# cmem7 register map
File version: 1.0
Registers are 32-bit, read-write, reset 0x0 unless marked. A register's access mark holds for its fields unless they carry their own. Offsets are from the block's base; [hi:lo] are bit positions; {n}, {i} and the like mark numbered series; 'fields as' and 'values as' point back to an identical list.

## USB
Base 0x41300000
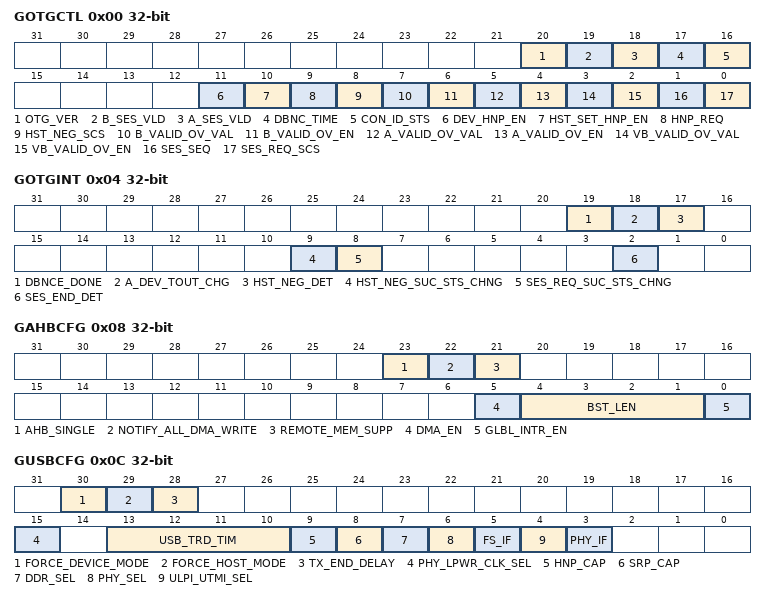
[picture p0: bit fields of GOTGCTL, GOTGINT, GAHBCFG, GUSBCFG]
0x00 GOTGCTL — Control and Status register
  [20] OTG_VER — If 0, OTG Version 1.3. If 1, OTG Version 2.0.
  [19] B_SES_VLD ro — B-Session Valid as a host
  [18] A_SES_VLD ro — A-Session Valid as a host
  [17] DBNC_TIME ro — the debounce time of a detected connection as a host
    0=DBNC_TIME_LONG (Long debounce time, used for physical connections (100ms + 2.5us)); 1=DBNC_TIME_SHORT (Short debounce time, used for soft connections (2.5us))
  [16] CON_ID_STS ro — Connector ID Status
    0=CON_ID_STS_A_DEVICE (in A-Device mode); 1=CON_ID_STS_B_DEVICE (in B-Device mode)
  [11] DEV_HNP_EN — Device HNP Enabled as a device
  [10] HST_SET_HNP_EN — Host Set HNP Enable as a host
  [9] HNP_REQ — sets this bit to initiate an HNP request to the connected USB host as a device
  [8] HST_NEG_SCS ro — sets when host negotiation is successful as a device.
  [7] B_VALID_OV_VAL — set Override value for Bvalid signal when GOTGCTL.BvalidOvEn is set as a device.
  [6] B_VALID_OV_EN — enable/disable the software to override the Bvalid signal using the GOTGCTL.BvalidOvVal as a device.
  [5] A_VALID_OV_VAL — set Override value for Avalid signal when GOTGCTL.AvalidOvEn is set as a host
  [4] A_VALID_OV_EN — enable/disable the software to override the Avalid signal using the GOTGCTL.AvalidOvVal as a host
  [3] VB_VALID_OV_VAL — set Override value for vbusvalid signal when GOTGCTL.VbvalidOvEn is set as a host
  [2] VB_VALID_OV_EN — enable/disable the software to override the Bvalid signal using the GOTGCTL.VbvalidOvVal as a host
  [1] SES_SEQ — set to initiate a session request on the USB as a device
  [0] SES_REQ_SCS ro — set when a session request initiation is successful as a device
0x04 GOTGINT — OTG interrupt Register
  [19] DBNCE_DONE — debounce is completed after the device connect as a host
  [18] A_DEV_TOUT_CHG — A-device has timed out while waiting for the B-device to connect
  [17] HST_NEG_DET — if set, detects a host negotiation request on the USB
  [9] HST_NEG_SUC_STS_CHNG — Host Negotiation Success Status Change
  [8] SES_REQ_SUC_STS_CHNG — Session Request Success Status Change
  [2] SES_END_DET — Set when the utmiotg_bvalid signal is deasserted
0x08 GAHBCFG — AHB Configuration Register
  [23] AHB_SINGLE — supports Single transfers for the remaining data in a transfer
  [22] NOTIFY_ALL_DMA_WRITE — enable the System DMA Done functionality for all the DMA write Transactions corresponding to the Channel/Endpoint
  [21] REMOTE_MEM_SUPP — enable the functionality to wait for the system DMA Done Signal for the DMA Write Transfers
  [5] DMA_EN — DMA enable
  [4:1] BST_LEN — Burst Length/Type
    0=BST_LEN_SINGLE (Single); 1=BST_LEN_INCR (INCR); 3=BST_LEN_INCR4 (INCR4); 5=BST_LEN_INCR8 (INCR8); 7=BST_LEN_INCR16 (INCR16)
  [0] GLBL_INTR_EN — Global Interrupt Enable
0x0C GUSBCFG — USB Configuration Register
  [30] FORCE_DEVICE_MODE
  [29] FORCE_HOST_MODE
  [28] TX_END_DELAY — Tx End Delay as a device
  [15] PHY_LPWR_CLK_SEL — 0, 480-MHz Internal PLL clock. 1, 48-MHz External Clock
  [13:10] USB_TRD_TIM — Specifies the response time for a MAC request to the Packet FIFO Controller (PFC) to fetch data from the DFIFO (SPRAM) as a device.
    5=When the MAC interface is 16-bit UTMI+; 9=When the MAC interface is 8-bit UTMI+
  [9] HNP_CAP — HNP-Capable
  [8] SRP_CAP — SRP-Capable
  [7] DDR_SEL — 0, Single Data Rate ULPI Interface, with 8-bit-wide data bus. 1, Double Data Rate ULPI Interface, with 4-bit-wide data bus
  [6] PHY_SEL — 0, USB 2.0 High-Speed PHY. 1, USB 1.1 full-speed serial transceiver
  [5] FS_IF — 1, 3-pin bidirectional. 0, 6-pin unidirectional
  [4] ULPI_UTMI_SEL — 1, ULPI. 0, UTMI+
  [3] PHY_IF — PHY Interface
    0=PHY_IF_8_BIT (8 bits); 1=PHY_IF_16_BIT (16 bits)
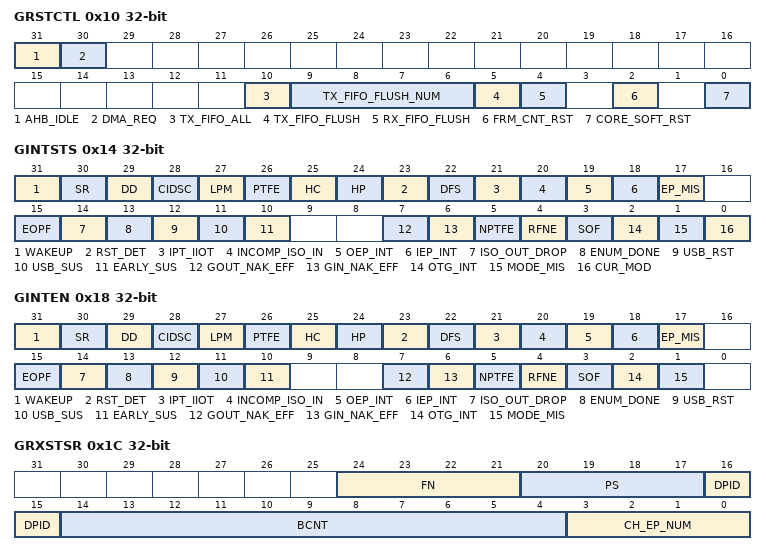
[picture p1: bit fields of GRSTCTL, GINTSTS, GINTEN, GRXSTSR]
0x10 GRSTCTL — Reset Register
  [31] AHB_IDLE ro — Indicates that the AHB Master State Machine is in the IDLE condition
  [30] DMA_REQ ro — Indicates that the DMA request is in progress
  [10] TX_FIFO_ALL — TxFIFO flush all FIFOs
  [9:6] TX_FIFO_FLUSH_NUM — This field indicates which of the 32 possible PHY devices are being accessed
  [5] TX_FIFO_FLUSH
  [4] RX_FIFO_FLUSH
  [2] FRM_CNT_RST — Host Frame Counter Reset
  [0] CORE_SOFT_RST — Core Soft Reset
0x14 GINTSTS — Interrupt Register
  [31] WAKEUP — Resume/Remote Wakeup Detected Interrupt
  [30] SR — Session Request/New Session Detected Interrupt
  [29] DD — A change in connector ID status
  [28] CIDSC — A change in connector ID status
  [27] LPM — LPM Transaction Received Interrupt
  [26] PTFE ro — Periodic TxFIFO Empty as a host
  [25] HC ro — an interrupt is pending on one of the channels of the core as a host
  [24] HP ro — a change in port status of one of the DWC_otg core ports as a host
  [23] RST_DET — reset detect as a device
  [22] DFS — Data Fetch Suspended as a device
  [21] IPT_IIOT — OUT Incomplete Periodic Transfer as a host or Incomplete Isochronous OUT Transfer as a device
  [20] INCOMP_ISO_IN — Incomplete Isochronous IN Transfer as a device
  [19] OEP_INT ro — OUT Endpoints Interrupt as a device
  [18] IEP_INT ro — IN Endpoints Interrupt as a device
  [17] EP_MIS ro — Endpoint Mismatch Interrupt as a device
  [15] EOPF — End of Periodic Frame Interrupt as a device
  [14] ISO_OUT_DROP — Drop an isochronous OUT packet while no space in RXFIFO as a device
  [13] ENUM_DONE — speed enumeration is complete as a device
  [12] USB_RST — A reset is detected on the USB as a device
  [11] USB_SUS — A suspend was detected on the USB as a device
  [10] EARLY_SUS — an Idle state has been detected on the USB For 3 ms as a device
  [7] GOUT_NAK_EFF ro — Global OUT NAK Effective as a device
  [6] GIN_NAK_EFF ro — Global IN Non-periodic NAK Effective as a device
  [5] NPTFE ro — Non-periodic TxFIFO Empty
  [4] RFNE ro — RxFIFO Non-Empty
  [3] SOF — Start of (micro)Frame
  [2] OTG_INT ro — OTG Interrupt
  [1] MODE_MIS — Mode Mismatch Interrupt
  [0] CUR_MOD ro — Current Mode of Operation
    0=CUR_MOD_DEVICE (device mode); 1=CUR_MOD_HOST (host mode)
0x18 GINTEN — Interrupt enable Register
  [31] WAKEUP — Resume/Remote Wakeup Detected Interrupt
  [30] SR — Session Request/New Session Detected Interrupt
  [29] DD — A change in connector ID status
  [28] CIDSC — A change in connector ID status
  [27] LPM — LPM Transaction Received Interrupt
  [26] PTFE — Periodic TxFIFO Empty as a host
  [25] HC — an interrupt is pending on one of the channels of the core as a host
  [24] HP — a change in port status of one of the DWC_otg core ports as a host
  [23] RST_DET — reset detect as a device
  [22] DFS — Data Fetch Suspended as a device
  [21] IPT_IIOT — OUT Incomplete Periodic Transfer as a host or Incomplete Isochronous OUT Transfer as a device
  [20] INCOMP_ISO_IN — Incomplete Isochronous IN Transfer as a device
  [19] OEP_INT — OUT Endpoints Interrupt as a device
  [18] IEP_INT — IN Endpoints Interrupt as a device
  [17] EP_MIS — Endpoint Mismatch Interrupt as a device
  [15] EOPF — End of Periodic Frame Interrupt as a device
  [14] ISO_OUT_DROP — Drop an isochronous OUT packet while no space in RXFIFO as a device
  [13] ENUM_DONE — speed enumeration is complete as a device
  [12] USB_RST — A reset is detected on the USB as a device
  [11] USB_SUS — A suspend was detected on the USB as a device
  [10] EARLY_SUS — an Idle state has been detected on the USB For 3 ms as a device
  [7] GOUT_NAK_EFF — Global OUT NAK Effective as a device
  [6] GIN_NAK_EFF — Global IN Non-periodic NAK Effective as a device
  [5] NPTFE — Non-periodic TxFIFO Empty
  [4] RFNE — RxFIFO Non-Empty
  [3] SOF — Start of (micro)Frame
  [2] OTG_INT — OTG
  [1] MODE_MIS — Mode Mismatch
0x1C GRXSTSR ro — Returns the contents of the top of the Receive FIFO
  [24:21] FN — the least significant 4 bits of the (micro)frame number in which the packet is received on the USB
  [20:17] PS — the status of the received packet
    1=PS_G_OUT_NAK (Global OUT NAK as a device); 2=PS_RX_DONE (data packet received); 3=PS_TX_DONE (transfer completed); 4=PS_SETUP_TX_DONE (SETUP transaction completed as a device); 5=PS_DATA_TOGGLE_ERR (Data toggle error as a host); 6=PS_SETUP_RX_DONE (SETUP data packet received as a device); 7=PS_CH_HALT (Channel halted as a host)
  [16:15] DPID — Data PID of the received packet
    0=DPID_DATA0 (DATA0); 1=DPID_DATA1 (DATA1); 2=DPID_DATA2 (DATA2); 3=DPID_MDATA (MDATA)
  [14:4] BCNT — byte count of the received packet
  [3:0] CH_EP_NUM — channel number as a host or EP number as a device
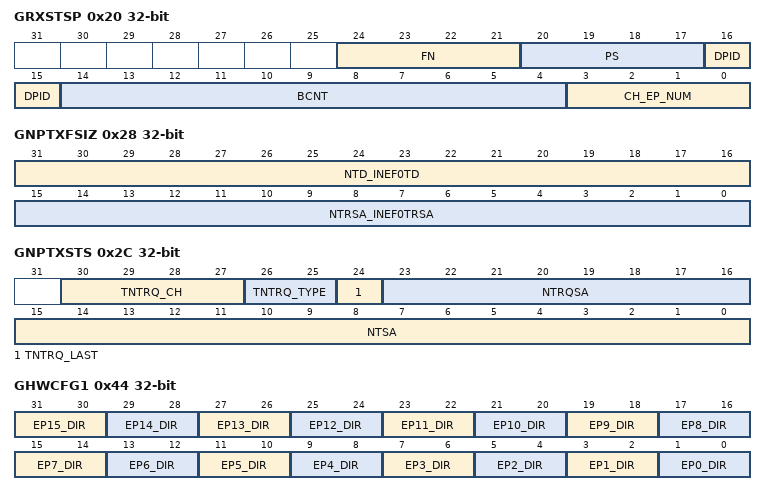
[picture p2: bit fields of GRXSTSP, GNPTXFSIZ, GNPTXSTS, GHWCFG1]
0x20 GRXSTSP ro — Pop the contents of the top of the Receive FIFO
  fields as GRXSTSR
0x24 GRXFSIZ 16-bit — This value is in terms of 32-bit words, 16 is minimize and 32768 is max
0x28 GNPTXFSIZ — Non-Periodic Transmit FIFO Size Register
  [31:16] NTD_INEF0TD — This value is in terms of 32-bit words, 16 is minimize and 32768 is max. Non-periodic TxFIFO Depth as a host or IN Endpoint TxFIFO 0 Depth as a device
  [15:0] NTRSA_INEF0TRSA — start address for Non-periodic Transmit FIFO RAM as a host or IN Endpoint FIFO0 Transmit RAM as a device
0x2C GNPTXSTS ro — Non-Periodic Transmit FIFO/Queue Status Register
  [30:27] TNTRQ_CH — Channel of top of the Non-periodic Transmit Request Queue
  [26:25] TNTRQ_TYPE — type in the Non-periodic Tx Request Queue that is currently being processed by the MAC
    0=TNTRQ_TYPE_OUT_TOKEN (OUT token); 1=TNTRQ_TYPE_OUT_ZERO_LENGTH_PACKET (OUT Zero-length transmit packet); 2=TNTRQ_TYPE_CSPLIT_TOKEN (CSPLIT token); 3=TNTRQ_TYPE_CH_HALT_CMD (Channel halt command)
  [24] TNTRQ_LAST — last Entry in the Non-periodic Tx Request Queue that is currently being processed by the MAC
  [23:16] NTRQSA — the amount of free space available in the Non-periodic Transmit Request Queue, max is 8.
  [15:0] NTSA — the amount of free space available in the Non-periodic TxFIFO, max is 32768.
0x44 GHWCFG1 ro — User HW Config1 Register
  [all] fields
    0=EP_DIR_BI (IN and OUT endpoint); 1=EP_DIR_IN (IN endpointt); 2=EP_DIR_OUT (OUT endpoint)
  [2n+1:2n] EP{n}_DIR (n=1..15) — Endpoint {n} direction
  [1:0] EP0_DIR — Endpoint 0 direction, always Bidirection
0x54 GLPMCFG — Core LPM Configuration Register
  [0] EP0_DIR — LPM capability is enabled
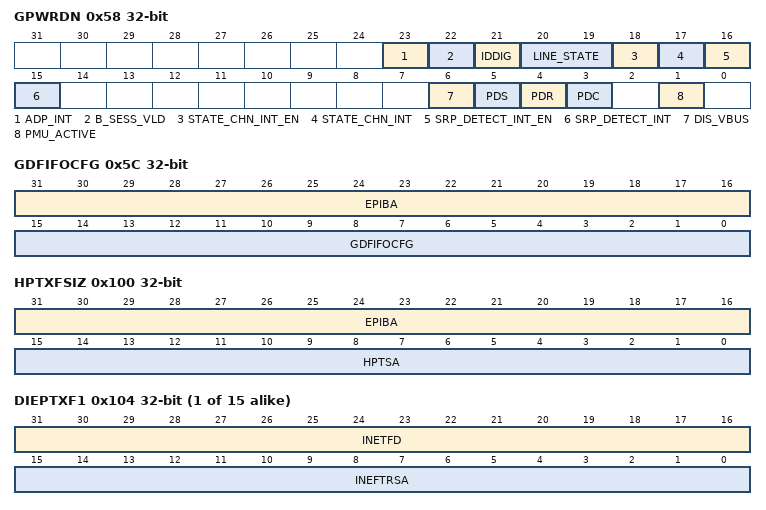
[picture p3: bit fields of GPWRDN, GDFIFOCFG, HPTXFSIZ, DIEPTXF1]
0x58 GPWRDN — Global Power Down Register
  [23] ADP_INT — set whenever there is a ADP event
  [22] B_SESS_VLD ro — B session valid status signal from the PHY
  [21] IDDIG ro — the status of the IDDIG signal. If 0, host mode. if 1, device mode
  [20:19] LINE_STATE ro — the current linestate on USB as seen by the PMU module
    0=LINE_STATE_DM0_DP0 (DM = 0, DP = 0); 1=LINE_STATE_DM0_DP1 (DM = 0, DP = 1); 2=LINE_STATE_DM1_DP0 (DM = 1, DP = 0)
  [18] STATE_CHN_INT_EN — Enable For Status Change Interrupt
  [17] STATE_CHN_INT — a status change in either the IDDIG or BSessVld signal
  [16] SRP_DETECT_INT_EN — Enable For SRPDetect Interrupt as a host
  [15] SRP_DETECT_INT — SRP has been detected by the PMU as a host
  [6] DIS_VBUS — Disable VBUS
  [5] PDS — If 0, DWC_otg is in ON state, or OFF state
  [4] PDR — If clear, Reset DWC_otg
  [3] PDC — Power Down Clamp is enabled
  [1] PMU_ACTIVE — PMU Active is enabled
0x5C GDFIFOCFG — Global DFIFO Software Config Register
  [31:16] EPIBA — This field provides the start address of the EP info controller
  [15:0] GDFIFOCFG — This field is for dynamic programming of the DFIFO Size.
0x100 HPTXFSIZ — Host Periodic Transmit FIFO Size Register
  [31:16] EPIBA — the size of the Periodic TxFIFO
  [15:0] HPTSA — start address of the Periodic TxFIFO
{0x100+4i} DIEPTXF{i} (i=1..15) — Device In Endpoint Transmit FIFO Size Register
  [31:16] INETFD — IN Endpoint TxFIFO Depth
  [15:0] INEFTRSA — IN Endpoint FIFOn Transmit RAM Start Address
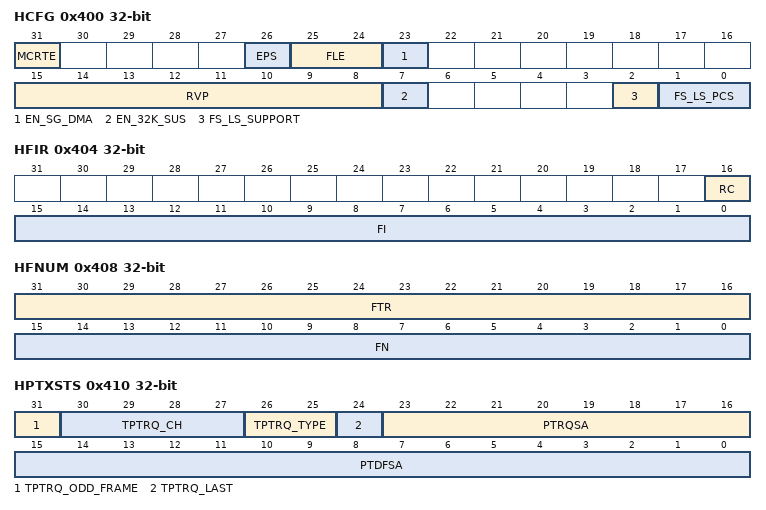
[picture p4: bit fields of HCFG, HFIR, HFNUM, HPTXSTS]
0x400 HCFG — Host Configuration Register
  [31] MCRTE — enable/disable the Host core to wait 200 PHY clock cycles at the end of Resume to change the opmode signal to the PHY to 00 after Suspend or LPM.
  [26] EPS — Enables periodic scheduling
  [25:24] FLE — the number of entries in the Frame list. 8 times of FLE
  [23] EN_SG_DMA — Enable Scatter/gather DMA in Host mode
  [15:8] RVP — ResValid number of clock cycles to detect a valid resume
  [7] EN_32K_SUS — Enable 32 KHz Suspend mode
  [2] FS_LS_SUPPORT — If set, FS/LS-only, even If the connected device can support HS
  [1:0] FS_LS_PCS — FS/LS PHY Clock Select as a host
    0=FS_LS_PCS_30_60M (PHY clock is running at 30/60 MHz); 1=FS_LS_PCS_48M (PHY clock is running at 48 MHz); 2=FS_LS_PCS_6M (PHY clock is running at 6 MHz)
0x404 HFIR — Host Frame Interval Register
  [16] RC — The HFIR can be dynamically reloaded during runtime if set
  [15:0] FI — IN Endpoint FIFOn Transmit RAM Start Address
0x408 HFNUM ro — Host Frame Number/Frame Time Remaining Register
  [31:16] FTR — amount of time remaining in the current microframe (HS) or Frame (FS/LS), in terms of PHY clocks
  [15:0] FN — This field increments when a new SOF is transmitted on the USB
0x410 HPTXSTS ro — Host Periodic Transmit FIFO/Queue Status Register
  [31] TPTRQ_ODD_FRAME — If set, send in odd (micro)Frame
  [30:27] TPTRQ_CH — Channel of top of the periodic Transmit Request Queue
  [26:25] TPTRQ_TYPE — type in the periodic Tx Request Queue that is currently being processed by the MAC
    0=TPTRQ_TYPE_OUT_TOKEN (OUT token); 1=TPTRQ_TYPE_ZERO_LENGTH_PACKET (Zero-length packet); 2=TPTRQ_TYPE_CSPLIT (CSPLIT); 3=TPTRQ_TYPE_CH_DIS_CMD (Channel Disable command)
  [24] TPTRQ_LAST — last Entry in the periodic Tx Request Queue that is currently being processed by the MAC
  [23:16] PTRQSA — Indicates the number of free locations available to be written in the Periodic Transmit Request Queue, max is 16
  [15:0] PTDFSA — Indicates the number of free locations available to be written to in the Periodic TxFIFO, max is 32768
0x414 HAINT ro — Host All Channels Interrupt Register
  [15:0] INT — Channel Interrupts, from 0 to 15.
0x418 HAINT_EN — Host All Channels Interrupt Enable Register
  [15:0] EN — Channel Interrupts Enable, from 0 to 15.
0x41C HFLBA — The starting address of the Frame list
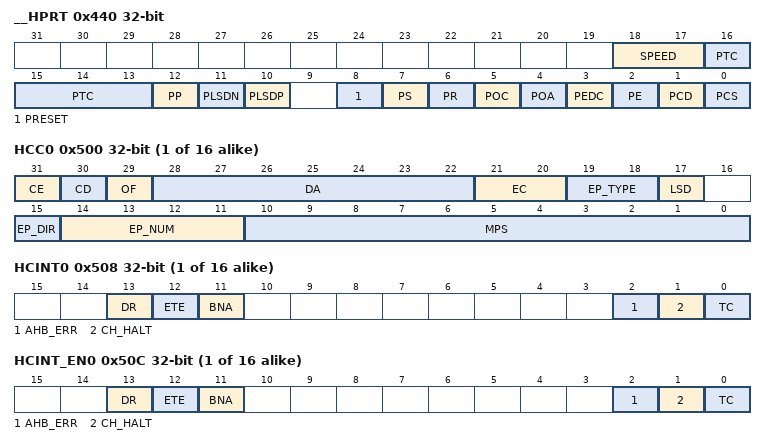
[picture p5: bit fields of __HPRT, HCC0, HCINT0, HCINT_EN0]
0x440 __HPRT — Host Port Control and Status Register
  [18:17] SPEED ro — Indicates the speed of the device attached to this port
    0=SPEED_HIGH (High speed); 1=SPEED_FULL (Full speed); 2=SPEED_LOW (low speed)
  [16:13] PTC — The application writes a nonzero value to this field to put the port into a Test mode
    0=PTC_TEST_DISABLE (Test mode disable); 1=PTC_TEST_J (Test_J mode); 2=PTC_TEST_K (Test_K mode); 3=PTC_TEST_SE0_NAK (Test_SE0_NAK mode); 4=PTC_TEST_PACKET (Test_Packet mode); 5=PTC_TEST_FORCE_ENABLE (Test_Force_Enable)
  [12] PP — this field to control power to this port. 1, power on
  [11] PLSDN — Logic level of D-
  [10] PLSDP — Logic level of D+
  [8] PRESET — sets this bit, a reset sequence is started on this port
  [7] PS — Sets this bit to put this port in Suspend mode
  [6] PR — Application and Core all can perform resume by setting, then clear it whatever resume is success or not
  [5] POC — Set if when the status of the Port Overcurrent Active bit (bit 4) in this register changes
  [4] POA ro — Indicates the overcurrent condition of the port
  [3] PEDC — Set if when the status of the Port Enable (bit 2) of this register changes
  [2] PE — Port Enable
  [1] PCD — A device connection is detected
  [0] PCS ro — If a device is attached to the port
{0x500+0x20*i} HCC{i} (i=0..15) — Host Channel Characteristics Register
  [31] CE — If the descriptor structure and data buffer are ready or not yet.
  [30] CD — sets this bit to stop transmitting/receiving data on a channel.
  [29] OF — The frame is odd or even.
  [28:22] DA — This field selects the specific device serving as the data source or sink.
  [21:20] EC — Multi Count (MC) / Error Count (EC).
  [19:18] EP_TYPE — Indicates the transfer type selected.
    0=EP_TYPE_CTRL (Control); 1=EP_TYPE_ISOCHRONOUS (Isochronous); 2=EP_TYPE_BULK (bulk); 3=EP_TYPE_INT (Interrupt)
  [17] LSD — indicate that this channel is communicating to a low-speed device.
  [15] EP_DIR — Indicates whether the transaction is IN or OUT. 0, OUT. 1, IN
  [14:11] EP_NUM — Indicates the endpoint number on the device serving as the data source or sink.
  [10:0] MPS — Indicates the maximum packet size of the associated endpoint
{0x508+0x20*i} HCINT{i} (i=0..15) — Host Channel Interrupt Register
  [13] DR — the corresponding channel's descriptor list rolls over
  [12] ETE — 3 consecutive transaction errors occurred on the USB bus
  [11] BNA — Buffer Not Available
  [2] AHB_ERR — there is an AHB error during AHB read/write
  [1] CH_HALT — Indicates the endpoint number on the device serving as the data source or sink.
  [0] TC — Transfer completed normally without any errors
{0x50C+0x20*i} HCINT_EN{i} (i=0..15) — Host Channel Interrupt Enable Register
  fields as HCINT0
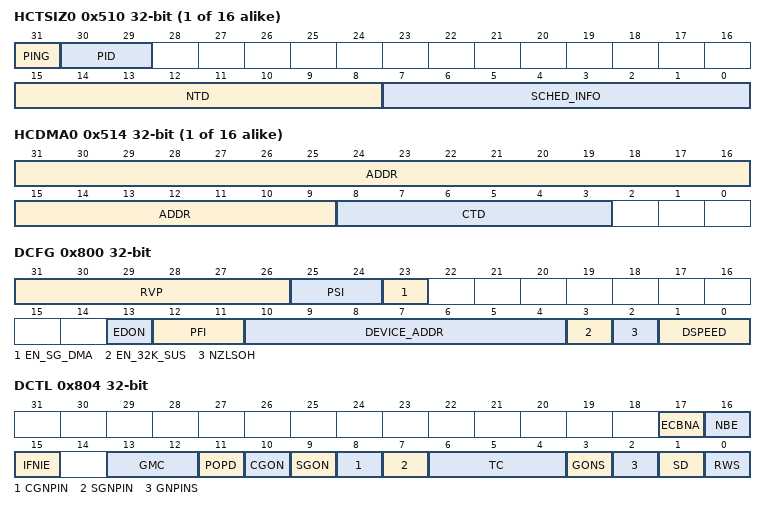
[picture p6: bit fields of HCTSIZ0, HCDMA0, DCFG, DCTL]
{0x510+0x20*i} HCTSIZ{i} (i=0..15) — Host Channel Transfer Size Register
  [31] PING — Setting this field to 1 directs the host to do PING protocol
  [30:29] PID — the type of PID to use for the initial transaction
    0=PID_DATA0 (Data 0); 1=PID_DATA2 (Data 2); 2=PID_DATA1 (Data 1); 3=PID_MDATA_SETUP (MDATA or SETUP)
  [15:8] NTD — Number of Transfer Descriptors.
  [7:0] SCHED_INFO — Every bit in this 8 bit register indicates scheduling for that microframe.Bit N indicates scheduling for Nth microframe scheduling for 8th microframe in that frame.
{0x514+0x20*i} HCDMA{i} (i=0..15) — Host Channel-n DMA Address Register
  [31:9] ADDR — he start address of 512 bytes page for Non-Isochronous
  [8:3] CTD — Number of Transfer Descriptors for Non-Isochronous
{0x51C+0x20*i} HCDMAB{i} (i=0..15) — Host Channel-n DMA Buffer Address Register
0x800 DCFG — Device Configuration Register
  [31:26] RVP — It controls the resume period when the core resumes from suspend
  [25:24] PSI — Periodic Scheduling Interval
    0=25% of the (micro)frame; 1=50% of the (micro)frame; 2=75% of the (micro)frame
  [23] EN_SG_DMA — enable the Scatter/Gather DMA operation
  [13] EDON — If set the core sets NAK after Bulk OUT transfer complete
  [12:11] PFI — Indicates the time within a (micro)frame at which the application must be notified using the End Of Periodic Frame Interrupt
    0=80% of the (micro)frame interval; 1=85% of the (micro)frame interval; 2=90% of the (micro)frame interval; 3=95% of the (micro)frame interval
  [10:4] DEVICE_ADDR — The application must program this field after every SetAddress control command
  [3] EN_32K_SUS — Enable 32 KHz Suspend mode
  [2] NZLSOH — select the handshake the core sends on receiving a non zero-length data packet during the OUT transaction of a control transfer's Status stage
  [1:0] DSPEED — the maximum speed the application can support
    0=DSPEED_HIGH (High speed (USB 2.0 PHY clock is 30 MHz or 60 MHz)); 1=DSPEED_FULL (Full speed (USB 2.0 PHY clock is 30 MHz or 60 MHz)); 2=DSPEED_LOW (Low speed (USB 1.1 transceiver clock is 6 MHz).); 3=DSPEED_FULL_48M (Full speed (USB 1.1 transceiver clock is 48 MHz).)
0x804 DCTL — Device Control Register
  [17] ECBNA — After receiving BNA interrupt, the core disables the endpoint
  [16] NBE — Set NAK automatically on babble
  [15] IFNIE — Ignore frame number for isochronous endpoints
  [13:12] GMC — GMC must be programmed only once after initialization. the number of packets to be serviced for that end point before moving to the next end point
  [11] POPD — Power-On Programming Done
  [10] CGON wo — A write to this field sets the Global OUT NAK.
  [9] SGON wo — A write to this field sets the Global OUT NAK
  [8] CGNPIN wo — A write to this field clears the Global Non-periodic IN NAK
  [7] SGNPIN wo — A write to this field sets the Global Non-periodic IN NAK
  [6:4] TC — Test Control
    0=TC_TEST_DISABLE (Test mode disable); 1=TC_TEST_J (Test_J mode); 2=TC_TEST_K (Test_K mode); 3=TC_TEST_SE0_NAK (Test_SE0_NAK mode); 4=TC_TEST_PACKET (Test_Packet mode); 5=TC_TEST_FORCE_ENABLE (Test_Force_Enable)
  [3] GONS ro — No data is written to the RxFIFO, irrespective of space availability..
  [2] GNPINS ro — A NAK handshake is sent out on all non-periodic IN endpoints, irrespective of the data availability in the transmit FIFO.
  [1] SD — If set, generates a device disconnect event to the USB host
  [0] RWS — If set, the core initiates remote signaling to wake the USB hosts
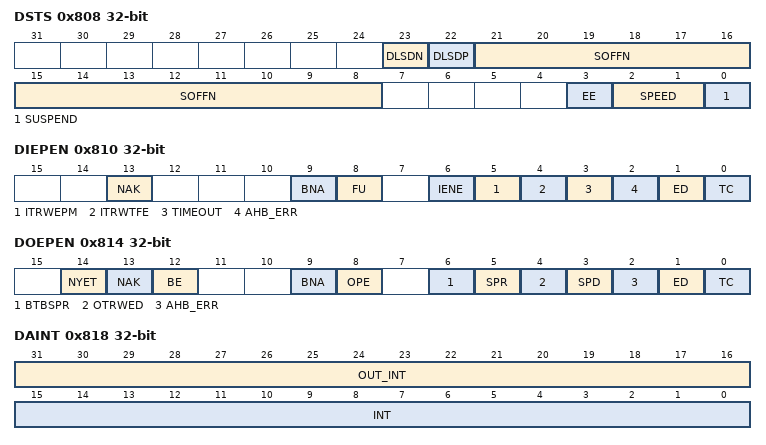
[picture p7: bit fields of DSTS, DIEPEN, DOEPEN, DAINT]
0x808 DSTS ro — Device Status Register
  [23] DLSDN — Logic level of D-
  [22] DLSDP — Logic level of D+
  [21:8] SOFFN — Frame or Microframe Number of the Received SOF
  [3] EE — reason of suspend state
  [2:1] SPEED — Indicates the speed at which the DWC_otg core has come up after speed detection through a chirp sequence
    0=SPEED_HIGH (High speed (USB 2.0 PHY clock is 30 MHz or 60 MHz)); 1=SPEED_FULL (Full speed (USB 2.0 PHY clock is 30 MHz or 60 MHz)); 2=SPEED_LOW (Low speed (USB 1.1 transceiver clock is 6 MHz).); 3=SPEED_FULL_48M (Full speed (USB 1.1 transceiver clock is 48 MHz).)
  [0] SUSPEND — this bit is set as long as a Suspend condition is detected on the USB
0x810 DIEPEN — Device IN Endpoint Common Interrupt Enable Register
  [13] NAK — NAK interrupt
  [9] BNA — BNA Interrupt
  [8] FU — Fifo Underrun
  [6] IENE — IN Endpoint NAK Effective
  [5] ITRWEPM — IN Token received with EP Mismatch
  [4] ITRWTFE — IN Token Received When TxFIFO Empty
  [3] TIMEOUT — Timeout Condition(Non-isochronous endpoints)
  [2] AHB_ERR — AHB Error Interrupt
  [1] ED — Endpoint Disabled Interrupt
  [0] TC — Transfer Completed Interrupt
0x814 DOEPEN — Device OUT Endpoint Common Interrupt Enable Register
  [14] NYET — NYET interrupt
  [13] NAK — NAK interrupt
  [12] BE — Babble Error interrupt
  [9] BNA — BNA Interrupt
  [8] OPE — OUT Packet Error
  [6] BTBSPR — Back-to-Back SETUP Packets Received, Applies to control OUT endpoints only
  [5] SPR — Status Phase Received
  [4] OTRWED — OUT Token Received when Endpoint Disabled, Applies to control OUT endpoints only
  [3] SPD — SETUP Phase Done, Applies to control endpoints only
  [2] AHB_ERR — AHB Error Interrupt
  [1] ED — Endpoint Disabled Interrupt
  [0] TC — Transfer Completed Interrupt
0x818 DAINT ro — Device All Channels Interrupt Register
  [31:16] OUT_INT — OUT Endpoint Interrupt Bits, from 0 to 15.
  [15:0] INT — IN Endpoint Interrupt Bits, from 0 to 15.
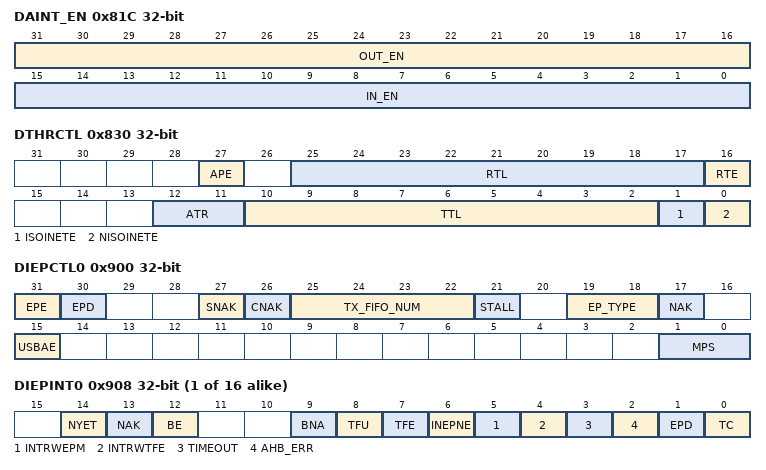
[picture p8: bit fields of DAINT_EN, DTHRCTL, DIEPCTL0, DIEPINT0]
0x81C DAINT_EN — Device All Channels Interrupt Enable Register
  [31:16] OUT_EN — OUT EP Interrupt Enable, from 0 to 15.
  [15:0] IN_EN — IN EP Interrupt Enable, from 0 to 15.
0x830 DTHRCTL — Device Threshold Control Register
  [27] APE — This bit controls internal DMA arbiter parking for IN endpoints
  [25:17] RTL — This field specifies Receive thresholding size in DWORDS
  [16] RTE — If set, the core enables thresholding in the receive direction
  [12:11] ATR — These bits define the ratio between the AHB threshold and the MAC threshold for the transmit path only.
    0=ATR_MAC_THRES_1_1 (AHB threshold = MAC threshold); 1=ATR_MAC_THRES_1_2 (AHB threshold = MAC threshold / 2); 2=ATR_MAC_THRES_1_4 (AHB threshold = MAC threshold / 4); 3=ATR_MAC_THRES_1_8 (AHB threshold = MAC threshold / 8)
  [10:2] TTL — This field specifies Transmit thresholding size in DWORDS
  [1] ISOINETE — ISO IN Endpoints Threshold Enable
  [0] NISOINETE — Non-ISO IN Endpoints Threshold Enable
0x834 DIEPEMPEN 16-bit — Device IN Endpoint FIFO Empty Interrupt Enable Register
0x900 DIEPCTL0 — Device Control IN Endpoint 0 Control Register
  [31] EPE — the descriptor structure and data buffer with data ready to transmit is setup
  [30] EPD — The application sets this bit to stop transmitting data on an endpoint even before the transfer for that endpoint is complete
  [27] SNAK wo — A write to this bit sets the NAK bit for the endpoint
  [26] CNAK wo — A write to this bit clears the NAK bit for the endpoint
  [25:22] TX_FIFO_NUM — TxFIFO Number
  [21] STALL — The application sets this bit, and the core clears it when a SETUP token is received for this endpoint
  [19:18] EP_TYPE ro — Hardcoded to 00 for control
  [17] NAK ro — The core is transmitting NAK handshakes on this endpoint
  [15] USBAE ro — Always 1, indicating that control endpoint 0 is always active in all configurations and interfaces
  [1:0] MPS — Indicates the maximum packet size of the associated endpoint, applies to IN and OUT endpoints
    0=64 Bytes; 1=32 Bytes; 2=16 Bytes; 3=8 Bytes
{0x908+0x20*i} DIEPINT{i} (i=0..15) — Device IN Endpoint-n Interrupt Register
  [14] NYET — a NYET response is transmitted
  [13] NAK — a NAK is transmitted
  [12] BE — Babble Error
  [9] BNA — Buffer Not Available
  [8] TFU — Transmit FIFO Underrun
  [7] TFE ro — either half or completely empty depending on GAHBCFG.NPTxFEmpLvl
  [6] INEPNE — IN Endpoint NAK Effective
  [5] INTRWEPM — IN Token Received with EP Mismatch
  [4] INTRWTFE — IN Token Received When TxFIFO is Empty
  [3] TIMEOUT — a timeout condition on the USB for the last IN token on this endpoint
  [2] AHB_ERR — there is an AHB error during AHB read/write
  [1] EPD — Endpoint Disabled Interrupt
  [0] TC — Transfer completed normally without any errors
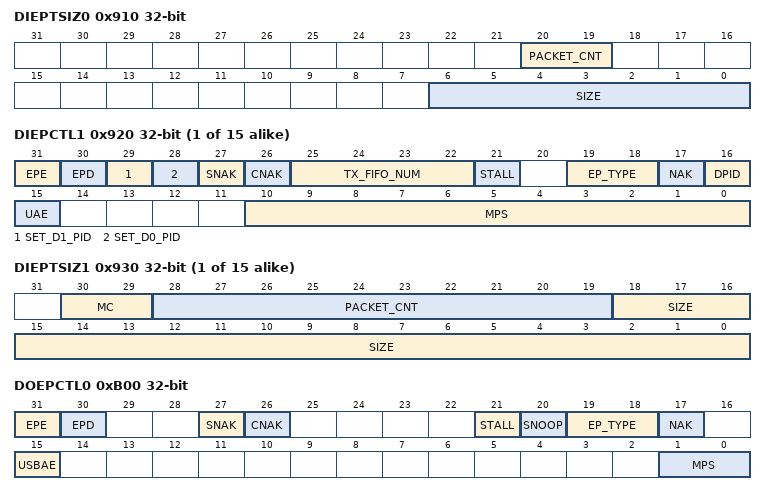
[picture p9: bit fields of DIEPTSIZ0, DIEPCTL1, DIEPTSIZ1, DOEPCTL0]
0x910 DIEPTSIZ0 — Device IN Endpoint 0 Transfer Size Register
  [20:19] PACKET_CNT — the total number of USB packets
  [6:0] SIZE — Indicates the transfer size in bytes for endpoint 0
{0x914+0x20*i} DIEPDMA{i} (i=0..15) — Device IN Endpoint-n DMA Address Register
{0x918+0x20*i} DTXFSA{i} (i=0..15) 16-bit — Device IN Endpoint-n Transmit FIFO Space Avail Register
{0x91C+0x20*i} DIEPDMAB{i} (i=0..15) ro — Device IN Endpoint-n DMA Buffer Address Register
{0x900+0x20*i} DIEPCTL{i} (i=1..15) — Device IN Endpoint N Control Register
  [31] EPE — the descriptor structure and data buffer with data ready to transmit is setup
  [30] EPD — The application sets this bit to stop transmitting data on an endpoint even before the transfer for that endpoint is complete
  [29] SET_D1_PID wo — Set DATA1 PID
  [28] SET_D0_PID wo — Set DATA0 PID
  [27] SNAK wo — A write to this bit sets the NAK bit for the endpoint
  [26] CNAK wo — A write to this bit clears the NAK bit for the endpoint
  [25:22] TX_FIFO_NUM — TxFIFO Number
  [21] STALL — To non-control, non-isochronous IN endpoints, stall all tokens. To control endpoints, response an ACK
  [19:18] EP_TYPE — Indicates the transfer type selected.
    values as HCC0.EP_TYPE
  [17] NAK ro — The core is transmitting NAK handshakes on this endpoint if set
  [16] DPID ro — Endpoint Data PID
  [15] UAE — Indicates whether this endpoint is active
  [10:0] MPS — Indicates the maximum packet size of the associated endpoint
{0x910+0x20*i} DIEPTSIZ{i} (i=1..15) — Device IN Endpoint-n Transfer Size Register
  [30:29] MC — the number of packets per microframe to periodic IN endpoints. The number of packets must be fetched per non-periodic IN endpoints
  [28:19] PACKET_CNT — the total number of USB packets
  [18:0] SIZE — Indicates the transfer size in bytes for endpoint 0
0xB00 DOEPCTL0 — Device Control OUT Endpoint 0 Control Register
  [31] EPE — the descriptor structure and data buffer with data ready to receive data is setup
  [30] EPD ro — The application cannot disable control OUT endpoint 0
  [27] SNAK wo — A write to this bit sets the NAK bit for the endpoint
  [26] CNAK wo — A write to this bit clears the NAK bit for the endpoint
  [21] STALL — The application sets this bit, and the core clears it when a SETUP token is received for this endpoint
  [20] SNOOP — does not check if the OUT packets are correct before transferring
  [19:18] EP_TYPE ro — Hardcoded to 00 for control
  [17] NAK ro — The core is transmitting NAK handshakes on this endpoint
  [15] USBAE ro — Always 1, indicating that control endpoint 0 is always active in all configurations and interfaces
  [1:0] MPS — Indicates the maximum packet size of the associated endpoint, applies to IN and OUT endpoints
    0=64 Bytes; 1=32 Bytes; 2=16 Bytes; 3=8 Bytes
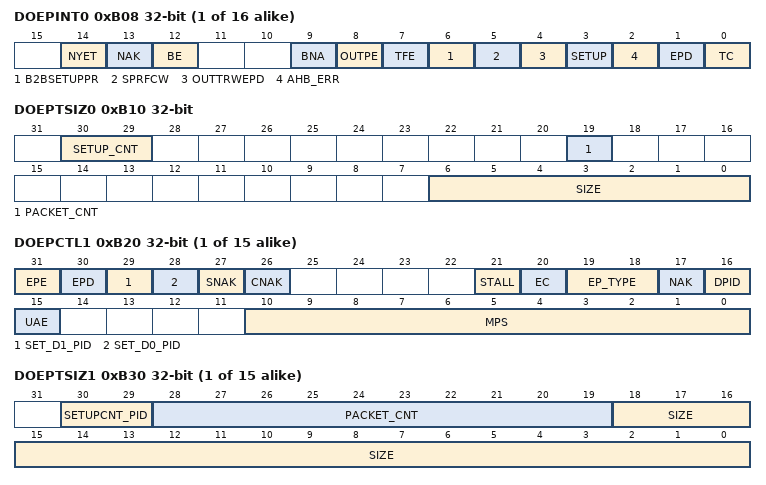
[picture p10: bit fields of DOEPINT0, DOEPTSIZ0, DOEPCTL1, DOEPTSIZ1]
{0xB08+0x20*i} DOEPINT{i} (i=0..15) — Device OUT Endpoint-n Interrupt Register
  [14] NYET — a NYET response is transmitted
  [13] NAK — a NAK is transmitted
  [12] BE — Babble Error
  [9] BNA — Buffer Not Available
  [8] OUTPE — an overflow or a CRC error for an OUT packet
  [7] TFE ro — either half or completely empty depending on GAHBCFG.NPTxFEmpLvl
  [6] B2BSETUPPR — to Control OUT endpoints only, received more than three back-to-back SETUP packets for this particular endpoint
  [5] SPRFCW — Only for Control OUT endpoints, the host has switched from data phase to the status phase of a Control Write transfer
  [4] OUTTRWEPD — OUT Token Received When Endpoint Disabled
  [3] SETUP — Only for Control OUT endpoints, the SETUP phase for the control endpoint is complete
  [2] AHB_ERR — there is an AHB error during AHB read/write
  [1] EPD — Endpoint Disabled Interrupt
  [0] TC — Transfer completed normally without any errors
0xB10 DOEPTSIZ0 — Device OUT Endpoint 0 Transfer Size Register
  [30:29] SETUP_CNT — the number of back-to-back SETUP data packets the endpoint can receive
  [19] PACKET_CNT — This field is decremented to zero after a packet is written into the RxFIFO
  [6:0] SIZE — Indicates the transfer size in bytes for endpoint 0
{0xB14+0x20*i} DOEPDMA{i} (i=0..15) — Device OUT Endpoint-n DMA Address Register
{0xB1C+0x20*i} DOEPDMAB{i} (i=0..15) ro — Device OUT Endpoint-n DMA Buffer Address Register
{0xB00+0x20*i} DOEPCTL{i} (i=1..15) — Device OUT Endpoint N Control Register
  [31] EPE — the descriptor structure and data buffer with data ready to receive data is setup
  [30] EPD — The application sets this bit to stop receiving data on an endpoint even before the transfer for that endpoint is complete
  [29] SET_D1_PID wo — Set DATA1 PID
  [28] SET_D0_PID wo — Set DATA0 PID
  [27] SNAK wo — A write to this bit sets the NAK bit for the endpoint
  [26] CNAK wo — A write to this bit clears the NAK bit for the endpoint
  [21] STALL — To non-control, non-isochronous OUT endpoints, stall all tokens. To control endpoints, response an ACK
  [20] EC — Doesn't check the correctness of OUT packets before transferring
  [19:18] EP_TYPE — Indicates the transfer type selected.
    values as HCC0.EP_TYPE
  [17] NAK ro — The core is transmitting NAK handshakes on this endpoint if set
  [16] DPID ro — Endpoint Data PID
  [15] UAE — Indicates whether this endpoint is active
  [10:0] MPS — Indicates the maximum packet size of the associated endpoint
{0xB10+0x20*i} DOEPTSIZ{i} (i=1..15) — Device OUT Endpoint-n Transfer Size Register
  [30:29] SETUPCNT_PID — To control OUT Endpoints only, back-to-back SETUP data packets. To isochronous OUT endpoints, data PID received in the last packet
  [28:19] PACKET_CNT — the total number of USB packets
  [18:0] SIZE — Indicates the transfer size in bytes for endpoint 0
